# PIC32MZ2048EFM144 register map
Registers are 32-bit, access not given, reset 0x0 unless marked. A register's access mark holds for its fields unless they carry their own. Offsets are from the block's base; [hi:lo] are bit positions; {n}, {i} and the like mark numbered series.

## PORTJ — PORTJ peripheral
Base 0xBF860800
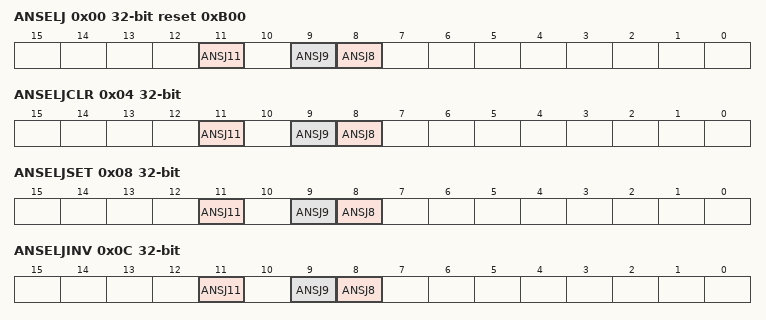
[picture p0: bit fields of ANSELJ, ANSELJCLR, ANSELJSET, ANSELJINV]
0x00 ANSELJ reset 0xB00
  [11] ANSJ11, [9] ANSJ9, [8] ANSJ8
0x04 ANSELJCLR
  [11] ANSJ11, [9] ANSJ9, [8] ANSJ8
0x08 ANSELJSET
  [11] ANSJ11, [9] ANSJ9, [8] ANSJ8
0x0C ANSELJINV
  [11] ANSJ11, [9] ANSJ9, [8] ANSJ8
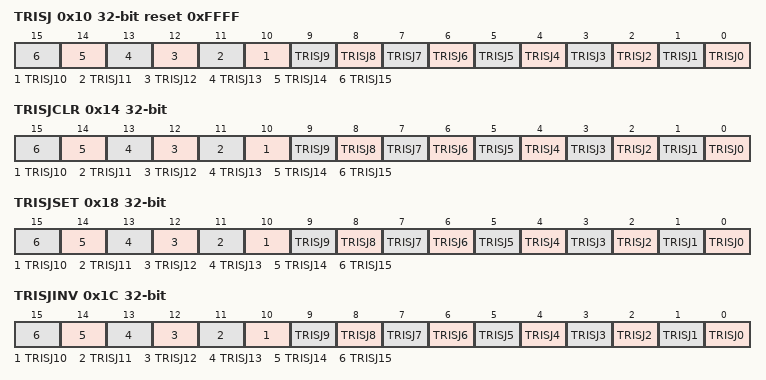
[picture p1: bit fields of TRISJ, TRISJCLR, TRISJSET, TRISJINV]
0x10 TRISJ reset 0xFFFF
  [n] TRISJ{n} (n=0..15)
0x14 TRISJCLR
  [n] TRISJ{n} (n=0..15)
0x18 TRISJSET
  [n] TRISJ{n} (n=0..15)
0x1C TRISJINV
  [n] TRISJ{n} (n=0..15)
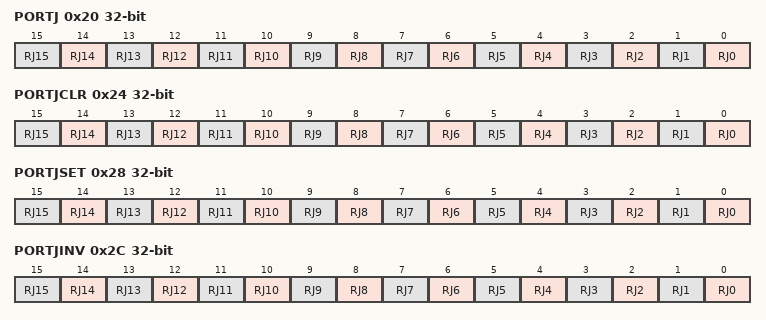
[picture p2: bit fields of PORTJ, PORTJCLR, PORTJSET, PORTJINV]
0x20 PORTJ
  [n] RJ{n} (n=0..15)
0x24 PORTJCLR
  [n] RJ{n} (n=0..15)
0x28 PORTJSET
  [n] RJ{n} (n=0..15)
0x2C PORTJINV
  [n] RJ{n} (n=0..15)
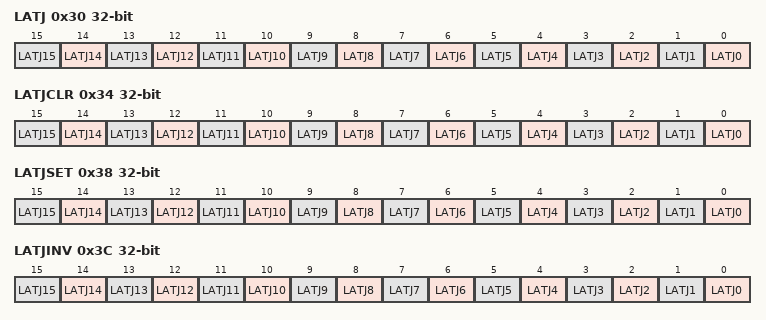
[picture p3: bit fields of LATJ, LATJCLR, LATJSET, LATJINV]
0x30 LATJ
  [n] LATJ{n} (n=0..15)
0x34 LATJCLR
  [n] LATJ{n} (n=0..15)
0x38 LATJSET
  [n] LATJ{n} (n=0..15)
0x3C LATJINV
  [n] LATJ{n} (n=0..15)
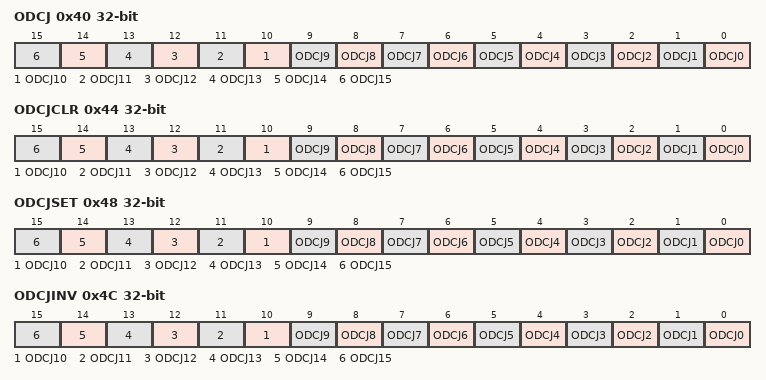
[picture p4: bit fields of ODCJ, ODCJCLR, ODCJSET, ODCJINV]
0x40 ODCJ
  [n] ODCJ{n} (n=0..15)
0x44 ODCJCLR
  [n] ODCJ{n} (n=0..15)
0x48 ODCJSET
  [n] ODCJ{n} (n=0..15)
0x4C ODCJINV
  [n] ODCJ{n} (n=0..15)
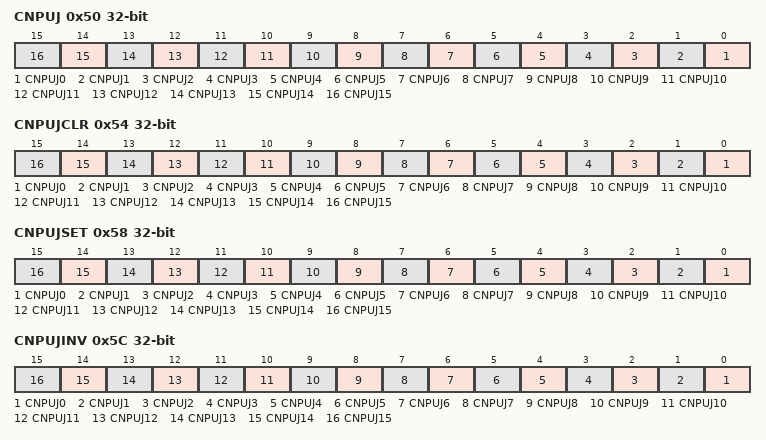
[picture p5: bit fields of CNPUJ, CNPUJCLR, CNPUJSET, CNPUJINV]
0x50 CNPUJ
  [n] CNPUJ{n} (n=0..15)
0x54 CNPUJCLR
  [n] CNPUJ{n} (n=0..15)
0x58 CNPUJSET
  [n] CNPUJ{n} (n=0..15)
0x5C CNPUJINV
  [n] CNPUJ{n} (n=0..15)
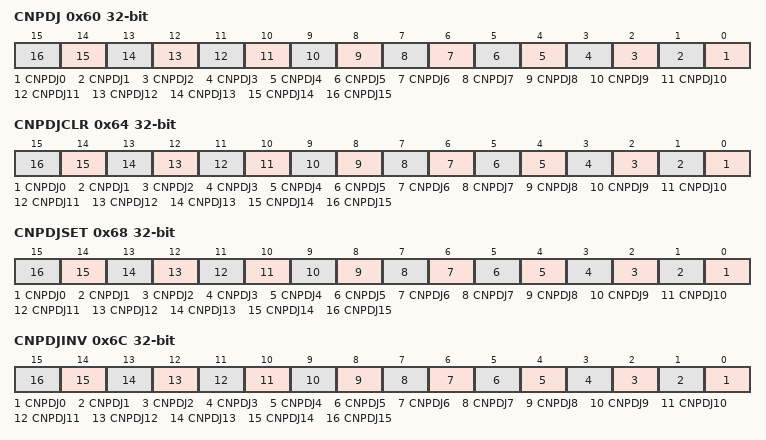
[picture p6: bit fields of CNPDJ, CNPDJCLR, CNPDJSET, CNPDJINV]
0x60 CNPDJ
  [n] CNPDJ{n} (n=0..15)
0x64 CNPDJCLR
  [n] CNPDJ{n} (n=0..15)
0x68 CNPDJSET
  [n] CNPDJ{n} (n=0..15)
0x6C CNPDJINV
  [n] CNPDJ{n} (n=0..15)
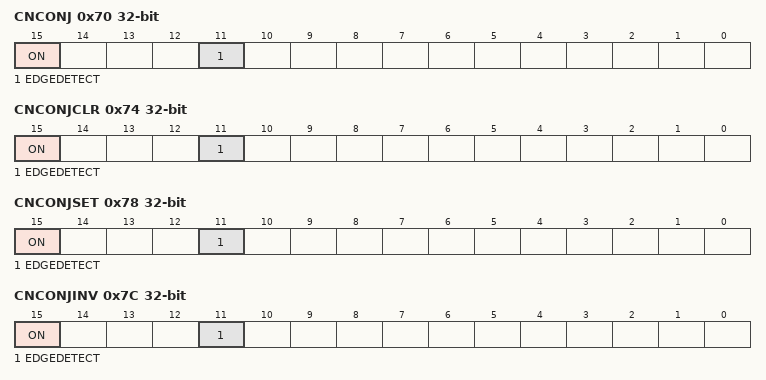
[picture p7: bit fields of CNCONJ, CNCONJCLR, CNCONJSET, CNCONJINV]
0x70 CNCONJ
  [15] ON, [11] EDGEDETECT
0x74 CNCONJCLR
  [15] ON, [11] EDGEDETECT
0x78 CNCONJSET
  [15] ON, [11] EDGEDETECT
0x7C CNCONJINV
  [15] ON, [11] EDGEDETECT
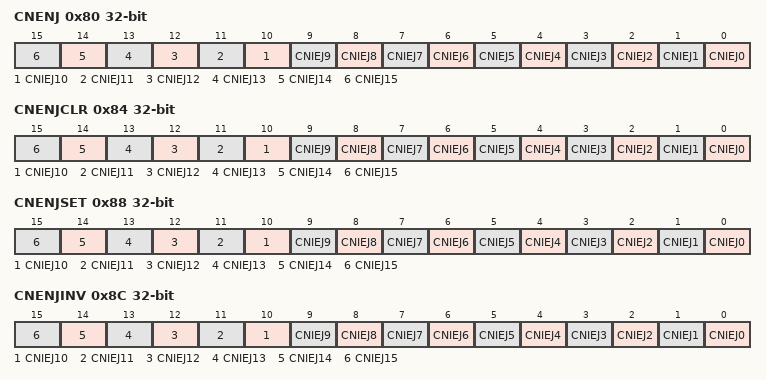
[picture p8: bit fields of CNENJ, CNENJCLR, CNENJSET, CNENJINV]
0x80 CNENJ
  [n] CNIEJ{n} (n=0..15)
0x84 CNENJCLR
  [n] CNIEJ{n} (n=0..15)
0x88 CNENJSET
  [n] CNIEJ{n} (n=0..15)
0x8C CNENJINV
  [n] CNIEJ{n} (n=0..15)
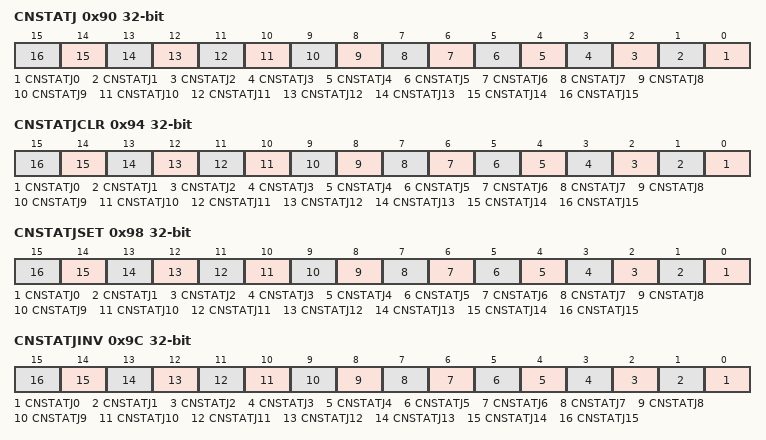
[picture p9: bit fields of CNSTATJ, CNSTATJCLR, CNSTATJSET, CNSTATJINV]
0x90 CNSTATJ
  [n] CNSTATJ{n} (n=0..15)
0x94 CNSTATJCLR
  [n] CNSTATJ{n} (n=0..15)
0x98 CNSTATJSET
  [n] CNSTATJ{n} (n=0..15)
0x9C CNSTATJINV
  [n] CNSTATJ{n} (n=0..15)
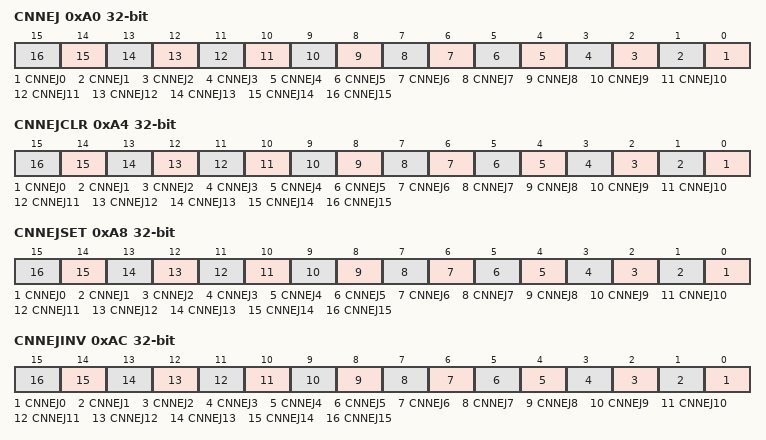
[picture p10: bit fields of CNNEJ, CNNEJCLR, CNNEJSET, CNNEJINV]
0xA0 CNNEJ
  [n] CNNEJ{n} (n=0..15)
0xA4 CNNEJCLR
  [n] CNNEJ{n} (n=0..15)
0xA8 CNNEJSET
  [n] CNNEJ{n} (n=0..15)
0xAC CNNEJINV
  [n] CNNEJ{n} (n=0..15)
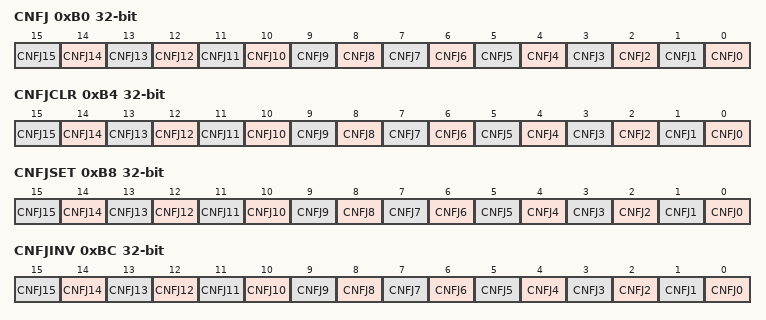
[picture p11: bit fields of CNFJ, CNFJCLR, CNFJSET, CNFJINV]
0xB0 CNFJ
  [n] CNFJ{n} (n=0..15)
0xB4 CNFJCLR
  [n] CNFJ{n} (n=0..15)
0xB8 CNFJSET
  [n] CNFJ{n} (n=0..15)
0xBC CNFJINV
  [n] CNFJ{n} (n=0..15)

## PORTK — PORTK peripheral
Base 0xBF860910
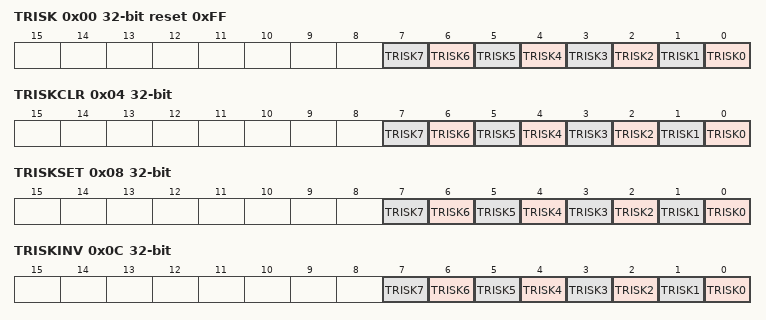
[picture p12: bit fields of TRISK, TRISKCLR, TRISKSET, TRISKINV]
0x00 TRISK reset 0xFF
  [n] TRISK{n} (n=0..7)
0x04 TRISKCLR
  [n] TRISK{n} (n=0..7)
0x08 TRISKSET
  [n] TRISK{n} (n=0..7)
0x0C TRISKINV
  [n] TRISK{n} (n=0..7)
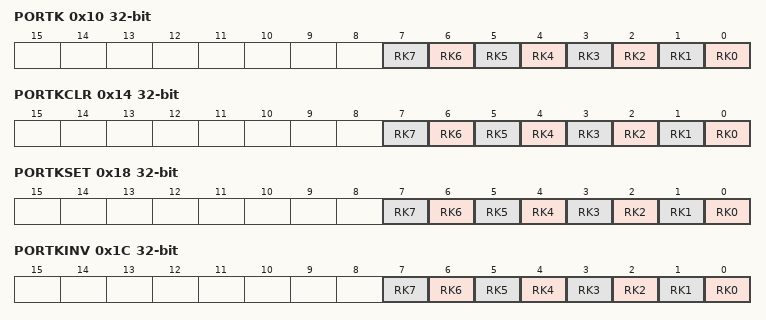
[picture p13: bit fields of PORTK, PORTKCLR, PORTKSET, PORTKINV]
0x10 PORTK
  [n] RK{n} (n=0..7)
0x14 PORTKCLR
  [n] RK{n} (n=0..7)
0x18 PORTKSET
  [n] RK{n} (n=0..7)
0x1C PORTKINV
  [n] RK{n} (n=0..7)
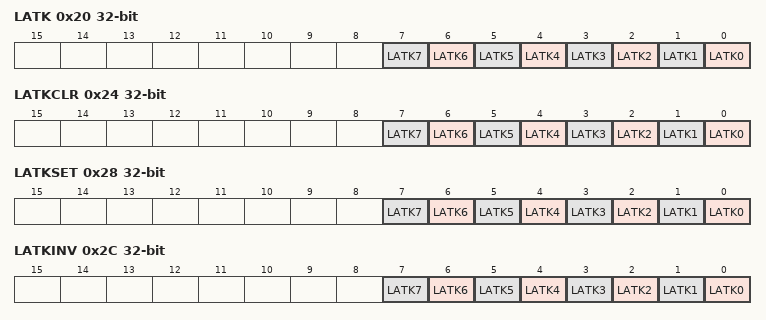
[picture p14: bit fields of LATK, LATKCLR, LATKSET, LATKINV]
0x20 LATK
  [n] LATK{n} (n=0..7)
0x24 LATKCLR
  [n] LATK{n} (n=0..7)
0x28 LATKSET
  [n] LATK{n} (n=0..7)
0x2C LATKINV
  [n] LATK{n} (n=0..7)
0x30 ODCK
  [n] ODCK{n} (n=0..7)
0x34 ODCKCLR
  [n] ODCK{n} (n=0..7)
0x38 ODCKSET
  [n] ODCK{n} (n=0..7)
0x3C ODCKINV
  [n] ODCK{n} (n=0..7)
0x40 CNPUK
  [n] CNPUK{n} (n=0..7)
0x44 CNPUKCLR
  [n] CNPUK{n} (n=0..7)
0x48 CNPUKSET
  [n] CNPUK{n} (n=0..7)
0x4C CNPUKINV
  [n] CNPUK{n} (n=0..7)
0x50 CNPDK
  [n] CNPDK{n} (n=0..7)
0x54 CNPDKCLR
  [n] CNPDK{n} (n=0..7)
0x58 CNPDKSET
  [n] CNPDK{n} (n=0..7)
0x5C CNPDKINV
  [n] CNPDK{n} (n=0..7)
0x60 CNCONK
  [15] ON, [11] EDGEDETECT
0x64 CNCONKCLR
  [15] ON, [11] EDGEDETECT
0x68 CNCONKSET
  [15] ON, [11] EDGEDETECT
0x6C CNCONKINV
  [15] ON, [11] EDGEDETECT
0x70 CNENK
  [n] CNIEK{n} (n=0..7)
0x74 CNENKCLR
  [n] CNIEK{n} (n=0..7)
0x78 CNENKSET
  [n] CNIEK{n} (n=0..7)
0x7C CNENKINV
  [n] CNIEK{n} (n=0..7)
0x80 CNSTATK
  [n] CNSTATK{n} (n=0..7)
0x84 CNSTATKCLR
  [n] CNSTATK{n} (n=0..7)
0x88 CNSTATKSET
  [n] CNSTATK{n} (n=0..7)
0x8C CNSTATKINV
  [n] CNSTATK{n} (n=0..7)
0x90 CNNEK
  [n] CNNEK{n} (n=0..7)
0x94 CNNEKCLR
  [n] CNNEK{n} (n=0..7)
0x98 CNNEKSET
  [n] CNNEK{n} (n=0..7)
0x9C CNNEKINV
  [n] CNNEK{n} (n=0..7)
0xA0 CNFK
  [n] CNFK{n} (n=0..7)
0xA4 CNFKCLR
  [n] CNFK{n} (n=0..7)
0xA8 CNFKSET
  [n] CNFK{n} (n=0..7)
0xAC CNFKINV
  [n] CNFK{n} (n=0..7)

## USBCRCON — USBCRCON peripheral
Base 0xBF884000
0x00 USBCRCON
  [26] USBIF, [25] USBRF, [24] USBWKUP, [9] USBIDOVEN, [8] USBIDVAL, [7] PHYIDEN, [6] VBUSMONEN, [5] ASVALMONEN, [4] BSVALMONEN, [3] SENDMONEN, [2] USBIE, [1] USBRIE, [0] USBWKUPEN
